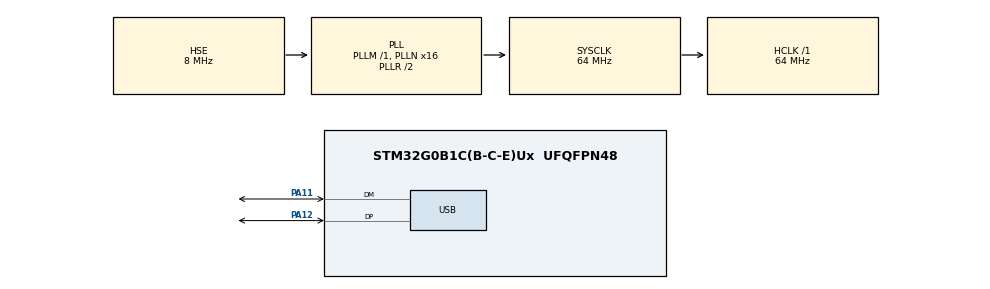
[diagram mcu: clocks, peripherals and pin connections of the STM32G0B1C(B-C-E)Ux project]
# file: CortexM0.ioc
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FREERTOS.Tasks01=defaultTask,0,128,StartDefaultTask,Default,NULL,Dynamic,NULL,NULL
Mcu.Family=STM32G0
Mcu.Name=STM32G0B1C(B-C-E)Ux
Mcu.Package=UFQFPN48
PA11\ [PA9].Mode=Device
PA11\ [PA9].Signal=USB_DM
PA12\ [PA10].Mode=Device
PA12\ [PA10].Signal=USB_DP
PA13.Mode=Serial_Wire
PA13.Signal=SYS_SWDIO
PA14-BOOT0.Mode=Serial_Wire
PA14-BOOT0.Signal=SYS_SWCLK
PF0-OSC_IN\ (PF0).Mode=HSE-External-Oscillator
PF0-OSC_IN\ (PF0).Signal=RCC_OSC_IN
PF1-OSC_OUT\ (PF1).Mode=HSE-External-Oscillator
PF1-OSC_OUT\ (PF1).Signal=RCC_OSC_OUT
ProjectManager.HeapSize=0x200
ProjectManager.StackSize=0x400
ProjectManager.TargetToolchain=Makefile
RCC.ADCFreq_Value=64000000
RCC.AHBFreq_Value=64000000
RCC.CortexFreq_Value=64000000
RCC.EXTERNAL_CLOCK_VALUE=48000
RCC.EnbaleCSS=true
RCC.HCLKFreq_Value=64000000
RCC.HSE_VALUE=8000000
RCC.HSI48_VALUE=48000000
RCC.HSI_VALUE=16000000
RCC.LSE_VALUE=32768
RCC.PLLN=16
RCC.PLLSourceVirtual=RCC_PLLSOURCE_HSE
RCC.SYSCLKFreq_VALUE=64000000
RCC.SYSCLKSource=RCC_SYSCLKSOURCE_PLLCLK
RCC.USBFreq_Value=48000000
RCC.VCOOutputFreq_Value=128000000
USB_DEVICE.CLASS_NAME_FS=CDC
USB_DEVICE.VirtualMode=Cdc
USB_DEVICE.VirtualModeFS=Cdc_FS
VP_FREERTOS_VS_CMSIS_V1.Mode=CMSIS_V1
VP_SYS_VS_DBSignals.Mode=DisableDeadBatterySignals
VP_USB_DEVICE_VS_USB_DEVICE_CDC_FS.Mode=CDC_FS
board=custom

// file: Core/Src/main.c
/* USER CODE BEGIN Header */
/**
 ******************************************************************************
 * @file           : main.c
 * @brief          : Main program body
 ******************************************************************************
 * @attention
 *
 * Copyright (c) 2022 STMicroelectronics.
 * All rights reserved.
 *
 * This software is licensed under terms that can be found in the LICENSE file
 * in the root directory of this software component.
 * If no LICENSE file comes with this software, it is provided AS-IS.
 *
 ******************************************************************************
 */
/* USER CODE END Header */
#include "main.h"
#include "cmsis_os.h"
#include "usb_device.h"

/* USER CODE BEGIN Includes */
#include "test.c"
/* USER CODE END Includes */

osThreadId defaultTaskHandle;

void SystemClock_Config(void);
static void MX_GPIO_Init(void);
void StartDefaultTask(void const *argument);

int main(void)
{

  /* MCU Configuration--------------------------------------------------------*/

  /* Reset of all peripherals, Initializes the Flash interface and the Systick. */
  HAL_Init();

  /* Configure the system clock */
  SystemClock_Config();

  /* Initialize all configured peripherals */
  MX_GPIO_Init();
  MX_USB_Device_Init();

  /* Create the thread(s) */
  /* definition and creation of defaultTask */
  osThreadDef(defaultTask, StartDefaultTask, osPriorityNormal, 0, 128);
  defaultTaskHandle = osThreadCreate(osThread(defaultTask), NULL);

  /* Start scheduler */
  osKernelStart();

  /* We should never get here as control is now taken by the scheduler */
  /* Infinite loop */
  /* USER CODE BEGIN WHILE */
  test();
  while (1)
  {
    /* USER CODE END WHILE */

  }
}

void SystemClock_Config(void)
{
  RCC_OscInitTypeDef RCC_OscInitStruct = {0};
  RCC_ClkInitTypeDef RCC_ClkInitStruct = {0};

  /** Configure the main internal regulator output voltage
   */
  HAL_PWREx_ControlVoltageScaling(PWR_REGULATOR_VOLTAGE_SCALE1);

  /** Initializes the RCC Oscillators according to the specified parameters
   * in the RCC_OscInitTypeDef structure.
   */
  RCC_OscInitStruct.OscillatorType = RCC_OSCILLATORTYPE_HSE | RCC_OSCILLATORTYPE_HSI48;
  RCC_OscInitStruct.HSEState = RCC_HSE_ON;
  RCC_OscInitStruct.HSI48State = RCC_HSI48_ON;
  RCC_OscInitStruct.PLL.PLLState = RCC_PLL_ON;
  RCC_OscInitStruct.PLL.PLLSource = RCC_PLLSOURCE_HSE;
  RCC_OscInitStruct.PLL.PLLM = RCC_PLLM_DIV1;
  RCC_OscInitStruct.PLL.PLLN = 16;
  RCC_OscInitStruct.PLL.PLLP = RCC_PLLP_DIV2;
  RCC_OscInitStruct.PLL.PLLQ = RCC_PLLQ_DIV2;
  RCC_OscInitStruct.PLL.PLLR = RCC_PLLR_DIV2;
  if (HAL_RCC_OscConfig(&RCC_OscInitStruct) != HAL_OK)
  {
    Error_Handler();
  }

  /** Initializes the CPU, AHB and APB buses clocks
   */
  RCC_ClkInitStruct.ClockType = RCC_CLOCKTYPE_HCLK | RCC_CLOCKTYPE_SYSCLK | RCC_CLOCKTYPE_PCLK1;
  RCC_ClkInitStruct.SYSCLKSource = RCC_SYSCLKSOURCE_PLLCLK;
  RCC_ClkInitStruct.AHBCLKDivider = RCC_SYSCLK_DIV1;
  RCC_ClkInitStruct.APB1CLKDivider = RCC_HCLK_DIV1;

  if (HAL_RCC_ClockConfig(&RCC_ClkInitStruct, FLASH_LATENCY_2) != HAL_OK)
  {
    Error_Handler();
  }

  /** Enables the Clock Security System
   */
  HAL_RCC_EnableCSS();
}

static void MX_GPIO_Init(void)
{

  /* GPIO Ports Clock Enable */
  __HAL_RCC_GPIOF_CLK_ENABLE();
  __HAL_RCC_GPIOA_CLK_ENABLE();
}

void StartDefaultTask(void const *argument)
{
  for (;;)
  {
    osDelay(1);
  }
}

void Error_Handler(void)
{
  __disable_irq();
  while (1)
  {
  }
}
